# M411_unitB register map
File version: 2.0.2.2
Registers are 32-bit, read-write, no defined reset value unless marked. A register's access mark holds for its fields unless they carry their own. Offsets are from the block's base; [hi:lo] are bit positions; {n}, {i} and the like mark numbered series.

## CPUIF — CPU Interface (CPUIF)
Base 0x400BC100
0x00 INTCR reset 0x0 — Interrupt Control Regiser
  [0] INT
0x04 INTCLR reset 0x0 — Interrupt Clear Register
  [0] CLR
0x08 INFOW reset 0x0 — Transmit Data Register
0x0C INFOR ro — Receive Data Register

## PH — Port H (PH)
Base 0x400C0700
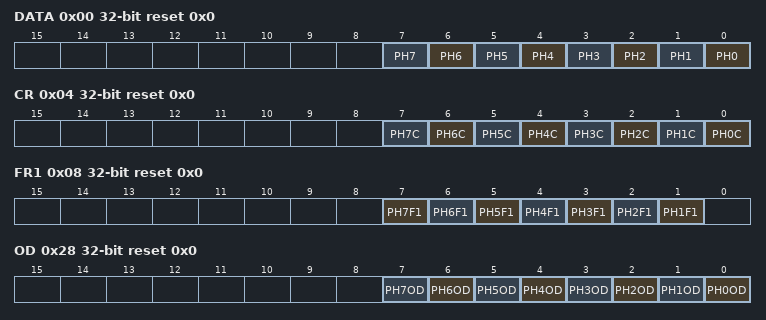
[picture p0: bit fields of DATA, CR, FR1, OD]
0x00 DATA reset 0x0 — Port H Data Register
  [n] PH{n} (n=0..7)
0x04 CR reset 0x0 — Port H Output Control Register
  [n] PH{n}C (n=0..7)
0x08 FR1 reset 0x0 — Port H Function Register 1
  [n] PH{n}F1 (n=1..7)
0x28 OD reset 0x0 — Port H Open-drain Control Register
  [n] PH{n}OD (n=0..7)
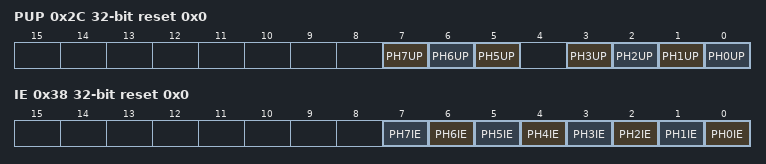
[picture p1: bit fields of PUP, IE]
0x2C PUP reset 0x0 — Port H Pull-up Control Register
  [7] PH7UP, [6] PH6UP, [5] PH5UP, [n] PH{n}UP (n=0..3)
0x30 PDN reset 0x0 — Port H Pull-down Control Register
  [4] PH4DN
0x38 IE reset 0x0 — Port H Input Control Register
  [n] PH{n}IE (n=0..7)

## PJ — Port J (PJ)
Base 0x400C0800
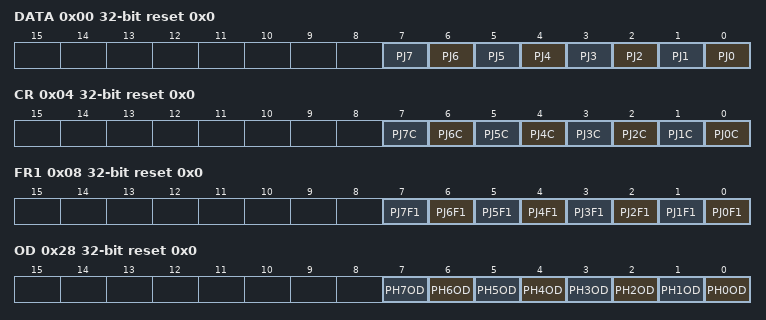
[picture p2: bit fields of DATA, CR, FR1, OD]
0x00 DATA reset 0x0 — Port J Data Register
  [n] PJ{n} (n=0..7)
0x04 CR reset 0x0 — Port J Output Control Register
  [n] PJ{n}C (n=0..7)
0x08 FR1 reset 0x0 — Port J Function Register 1
  [n] PJ{n}F1 (n=0..7)
0x28 OD reset 0x0 — Port J Open-drain Control Register
  [n] PH{n}OD (n=0..7)
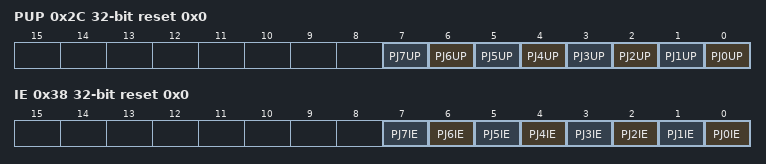
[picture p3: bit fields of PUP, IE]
0x2C PUP reset 0x0 — Port J Pull-up Control Register
  [n] PJ{n}UP (n=0..7)
0x38 IE reset 0x0 — Port J Input Control Register
  [n] PJ{n}IE (n=0..7)

## PK — Port K (PK)
Base 0x400C0900
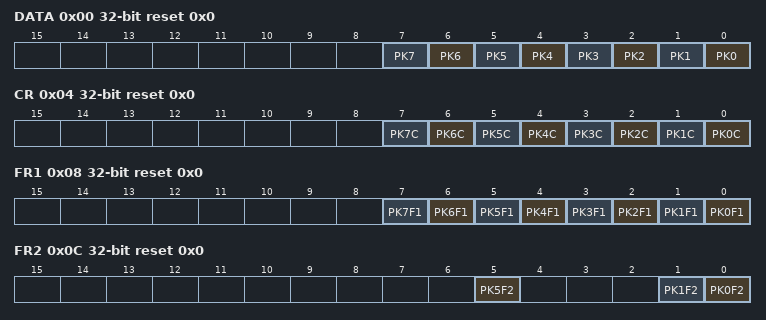
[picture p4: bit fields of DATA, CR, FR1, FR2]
0x00 DATA reset 0x0 — Port K Data Register
  [n] PK{n} (n=0..7)
0x04 CR reset 0x0 — Port K Output Control Register
  [n] PK{n}C (n=0..7)
0x08 FR1 reset 0x0 — Port K Function Register 1
  [n] PK{n}F1 (n=0..7)
0x0C FR2 reset 0x0 — Port K Function Register 2
  [5] PK5F2, [1] PK1F2, [0] PK0F2
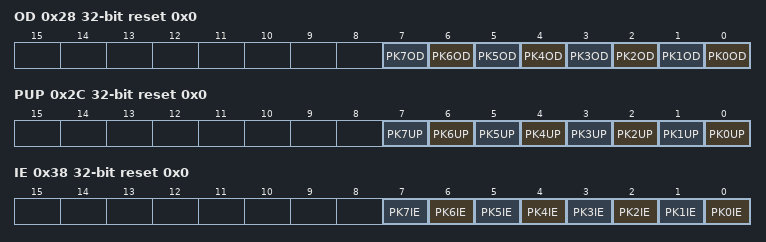
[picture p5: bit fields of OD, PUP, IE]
0x28 OD reset 0x0 — Port K Open-drain Control Register
  [n] PK{n}OD (n=0..7)
0x2C PUP reset 0x0 — Port K Pull-up Control Register
  [n] PK{n}UP (n=0..7)
0x38 IE reset 0x0 — Port K Input Control Register
  [n] PK{n}IE (n=0..7)

## PL — Port L (PL)
Base 0x400C0A00
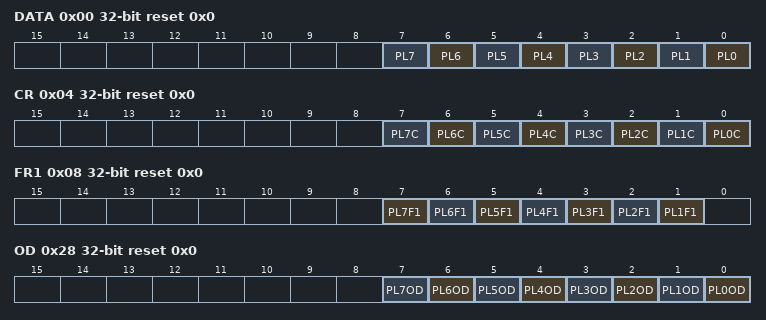
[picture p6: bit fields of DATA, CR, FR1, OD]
0x00 DATA reset 0x0 — Port L Data Register
  [n] PL{n} (n=0..7)
0x04 CR reset 0x0 — Port L Output Control Register
  [n] PL{n}C (n=0..7)
0x08 FR1 reset 0x0 — Port L Function Register 1
  [n] PL{n}F1 (n=1..7)
0x0C FR2 reset 0x0 — Port L Function Register 2
  [7] PL7F2
0x28 OD reset 0x0 — Port L Open-drain Control Register
  [n] PL{n}OD (n=0..7)
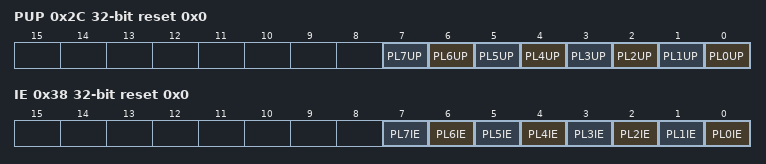
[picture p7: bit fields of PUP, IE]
0x2C PUP reset 0x0 — Port L Pull-up Control Register
  [n] PL{n}UP (n=0..7)
0x38 IE reset 0x0 — Port L Input Control Register
  [n] PL{n}IE (n=0..7)

## PM — Port M (PM)
Base 0x400C0B00
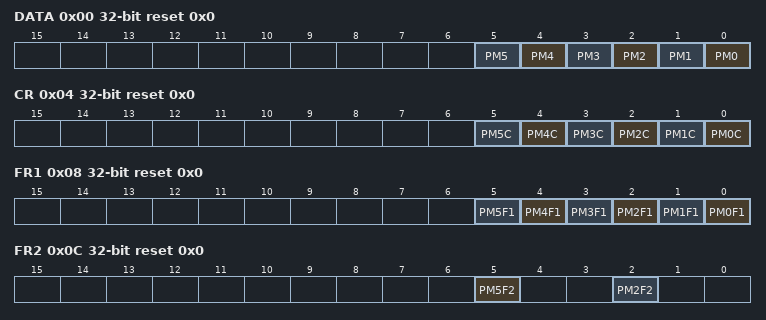
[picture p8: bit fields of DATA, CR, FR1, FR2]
0x00 DATA reset 0x0 — Port M Data Register
  [n] PM{n} (n=0..5)
0x04 CR reset 0x0 — Port M Output Control Register
  [n] PM{n}C (n=0..5)
0x08 FR1 reset 0x0 — Port M Function Register 1
  [n] PM{n}F1 (n=0..5)
0x0C FR2 reset 0x0 — Port M Function Register 2
  [5] PM5F2, [2] PM2F2
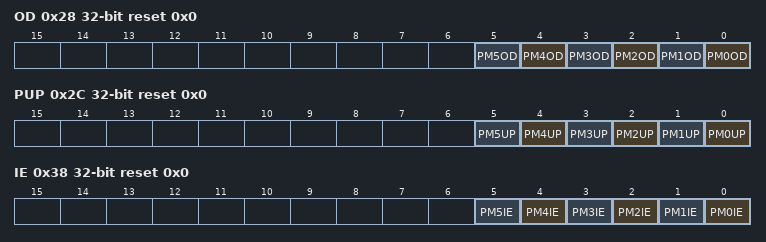
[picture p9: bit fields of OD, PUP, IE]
0x28 OD reset 0x0 — Port M Open-drain Control Register
  [n] PM{n}OD (n=0..5)
0x2C PUP reset 0x0 — Port M Pull-up Control Register
  [n] PM{n}UP (n=0..5)
0x38 IE reset 0x0 — Port M Input Control Register
  [n] PM{n}IE (n=0..5)

## PN — Port N (PN)
Base 0x400C0C00
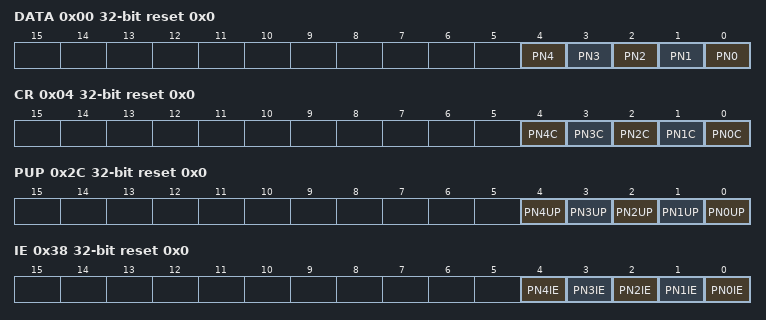
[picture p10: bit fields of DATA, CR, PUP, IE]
0x00 DATA reset 0x0 — Port N Data Register
  [n] PN{n} (n=0..4)
0x04 CR reset 0x0 — Port N Output Control Register
  [n] PN{n}C (n=0..4)
0x2C PUP reset 0x0 — Port N Pull-up Control Register
  [n] PN{n}UP (n=0..4)
0x38 IE reset 0x0 — Port N Input Control Register
  [n] PN{n}IE (n=0..4)

## TB3 — 16-bit Timer_Event Counter (TB)
Base 0x400C4300
Same registers: TB4 0x400C4400
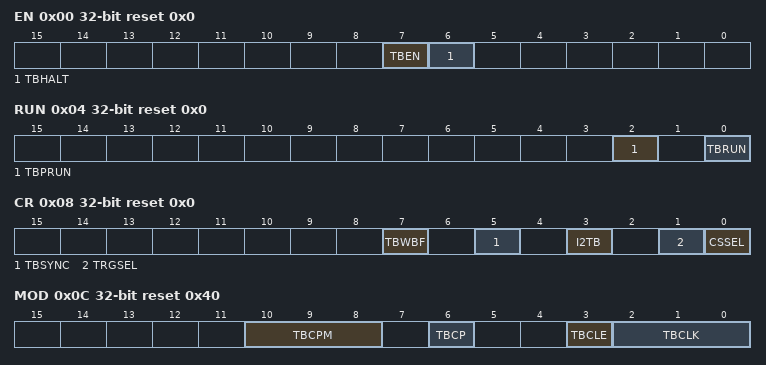
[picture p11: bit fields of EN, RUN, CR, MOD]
0x00 EN reset 0x0 — TB Enable Register
  [7] TBEN, [6] TBHALT
0x04 RUN reset 0x0 — TB RUN Register
  [2] TBPRUN, [0] TBRUN
0x08 CR reset 0x0 — TB Control Register
  [7] TBWBF, [5] TBSYNC, [3] I2TB, [1] TRGSEL, [0] CSSEL
0x0C MOD reset 0x40 — TB Mode Register
  [10:8] TBCPM, [6] TBCP wo, [3] TBCLE, [2:0] TBCLK
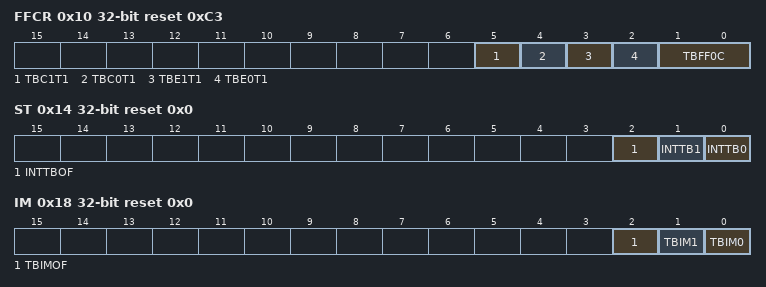
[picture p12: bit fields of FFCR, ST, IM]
0x10 FFCR reset 0xC3 — TB Flip-Flop Control Register
  [5] TBC1T1, [4] TBC0T1, [3] TBE1T1, [2] TBE0T1, [1:0] TBFF0C
0x14 ST ro reset 0x0 — TB Status Register
  [2] INTTBOF, [1] INTTB1, [0] INTTB0
0x18 IM reset 0x0 — TB Interrupt Mask Register
  [2] TBIMOF, [1] TBIM1, [0] TBIM0
0x1C UC ro reset 0x0 — TB Up-counter Capture Register
  [15:0] TBUC
0x20 RG0 reset 0x0 — TB RG0 Timer Register
  [15:0] TBRG0
0x24 RG1 reset 0x0 — TB RG1 Timer Register
  [15:0] TBRG1
0x28 CP0 ro reset 0x0 (reset mask 0xFFFF0000) — TB CP0 Capture Register
  [15:0] TBCP0
0x2C CP1 ro reset 0x0 (reset mask 0xFFFF0000) — TB CP1 Capture Register
  [15:0] TBCP1

## SC2 — SIO_UART (SC)
Base 0x400E1200
Same registers: SC3 0x400E1300, SC4 0x400E1400, SC5 0x400E1500
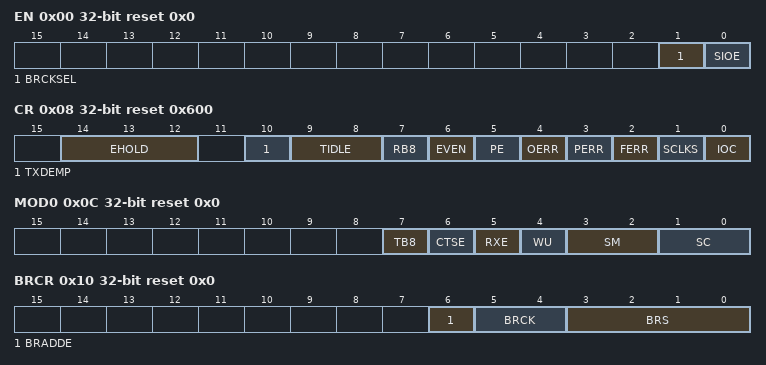
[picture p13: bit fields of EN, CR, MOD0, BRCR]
0x00 EN reset 0x0 — SC Enable Register
  [1] BRCKSEL, [0] SIOE
0x04 BUF reset 0x0 — SC Buffer Register
  [7:0] TB_RB
0x08 CR reset 0x600 — SC Control Register
  [14:12] EHOLD, [10] TXDEMP, [9:8] TIDLE, [7] RB8 ro, [6] EVEN, [5] PE, [4] OERR ro, [3] PERR ro, [2] FERR ro, [1] SCLKS, [0] IOC
0x0C MOD0 reset 0x0 — SC Mode Control Register 0
  [7] TB8, [6] CTSE, [5] RXE, [4] WU, [3:2] SM, [1:0] SC
0x10 BRCR reset 0x0 — SC Baud Rate Generator Control Register
  [6] BRADDE, [5:4] BRCK, [3:0] BRS
0x14 BRADD reset 0x0 — SC Baud Rate Generator Control Register 2
  [3:0] BRK
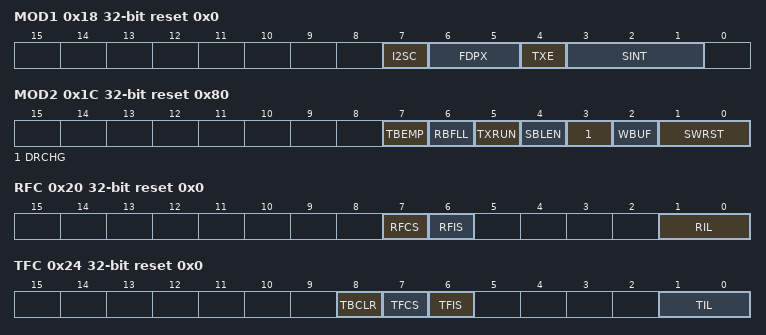
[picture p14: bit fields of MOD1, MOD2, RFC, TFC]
0x18 MOD1 reset 0x0 — SC Mode Control Register 1
  [7] I2SC, [6:5] FDPX, [4] TXE, [3:1] SINT
0x1C MOD2 reset 0x80 — SC Mode Control Register 2
  [7] TBEMP ro, [6] RBFLL ro, [5] TXRUN ro, [4] SBLEN, [3] DRCHG, [2] WBUF, [1:0] SWRST
0x20 RFC reset 0x0 — SC RX FIFO Configuration Register
  [7] RFCS wo, [6] RFIS, [1:0] RIL
0x24 TFC reset 0x0 — SC TX FIFO Configuration Register
  [8] TBCLR wo, [7] TFCS wo, [6] TFIS, [1:0] TIL
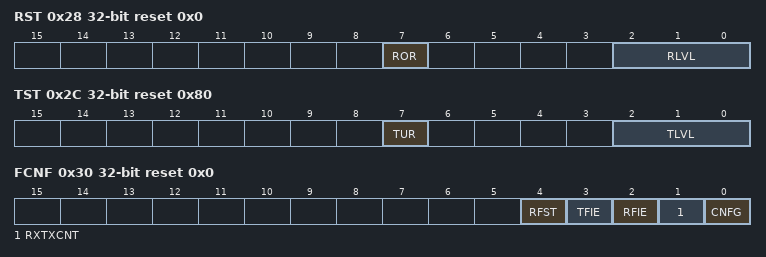
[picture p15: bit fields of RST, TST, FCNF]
0x28 RST ro reset 0x0 — SC RX FIFO Status Register
  [7] ROR, [2:0] RLVL
0x2C TST ro reset 0x80 — SC TX FIFO Status Register
  [7] TUR, [2:0] TLVL
0x30 FCNF reset 0x0 — SC FIFO Configuration Register
  [4] RFST, [3] TFIE, [2] RFIE, [1] RXTXCNT, [0] CNFG

## WD — Watchdog Timer (WD)
Base 0x400F2100
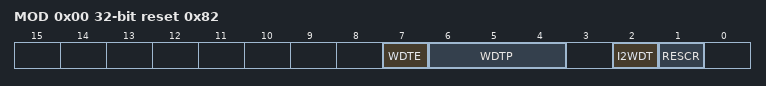
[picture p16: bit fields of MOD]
0x00 MOD reset 0x82 — Mode Register
  [7] WDTE, [6:4] WDTP, [2] I2WDT, [1] RESCR
0x04 CR wo reset 0x0 — Control Register
  [7:0] WDCR
0x08 FLG ro reset 0x0 — Flag Register
  [0] FLG

## CG — Clock Control (CG)
Base 0x400F3100
0x00 PROTECT reset 0xC1
  [7:0] CGPROTECT
0x04 OSCSEL reset 0x0 — High-speed oscillation select Register
  [1:0] OSCSEL
0x08 OSCSTF ro reset 0x0 — High-speed oscillation status Register
  [1:0] OSCF
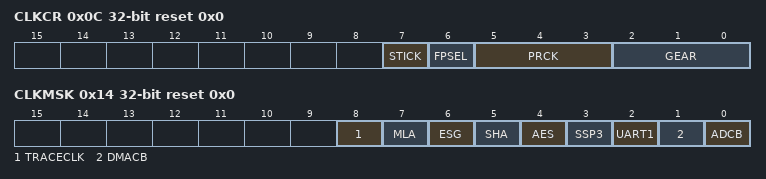
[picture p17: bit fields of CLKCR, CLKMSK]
0x0C CLKCR reset 0x0 — Clock Control Register
  [7] STICK, [6] FPSEL, [5:3] PRCK, [2:0] GEAR
0x10 STBYCR reset 0x0 — Standby Control Register
  [1:0] STBY
0x14 CLKMSK reset 0x0 — Clock supply control Register
  [8] TRACECLK, [7] MLA, [6] ESG, [5] SHA, [4] AES, [3] SSP3, [2] UART1, [1] DMACB, [0] ADCB

## FC — Flash Control (FC)
Base 0x5DFF0000
0x10 SECBIT reset 0x1 — Security Bit Register
  [0] SECBIT
0x20 PSR0 ro reset 0x1 (reset mask 0xFF) — Protect Status Register 0
  [n+16] BLK{n} (n=1..15), [n+8] PG{n} (n=0..7), [0] RDY_BSY
0x30 PSR1 ro reset 0x1 (reset mask 0xFFFF) — Protect Status Register 1
  [n] BLK{n} (n=16..31)
0x40 PSR2 ro reset 0x1 (reset mask 0xFFFF) — Protect Status Register 2
  [n-16] BLK{n} (n=32..47)
0x100 SR ro reset 0x0 — Status Register
  [24] WEABORT
0x104 SWPSR ro reset 0x0 (reset mask 0xFFFFF800) — Swap Status Register
  [10:8] SIZE, [7:2] FLG, [1:0] SWP
0x140 AREASEL reset 0x0 — Area Selection Register
  [10:8] AREA2, [6:4] AREA1, [2:0] AREA0
0x148 CR reset 0x0 — Control Register
  [2:0] WEABORT
0x14C STSCLR reset 0x0 — Status Clear Register
  [2:0] WEABORT
0x150 WCLKCR reset 0x0 — WCLK Configuration Register
  [4:0] DIV
0x154 PROGCR reset 0x0 — Program Counter Configuration Register
  [1:0] CNT
0x158 ERASECR reset 0x6 — Erase Counter Configuration Register
  [3:0] CNT
